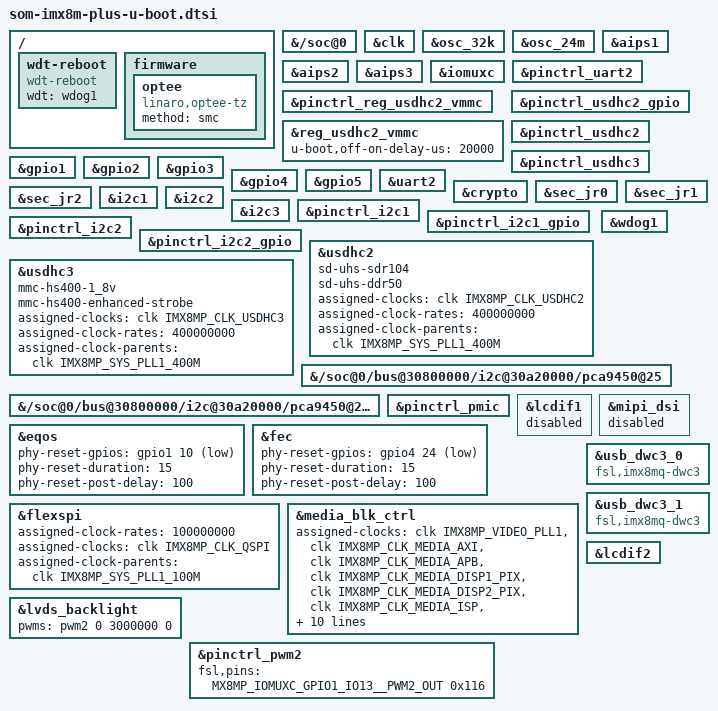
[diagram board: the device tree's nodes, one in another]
// SPDX-License-Identifier: GPL-2.0+
/*
 * Copyright 2019 NXP
 * Copyright 2021 CompuLab
 */

#include "imx8mp-sec-def.h"
#include "imx8mp-u-boot.dtsi"
/delete-node/ &binman;
#include "compulab-imx8mp-binman.dtsi"

/ {
	wdt-reboot {
		compatible = "wdt-reboot";
		wdt = <&wdog1>;
		bootph-pre-ram;
	};

	firmware {
		optee {
			compatible = "linaro,optee-tz";
			method = "smc";
		};
	};
};

&{/soc@0} {
	bootph-all;
	bootph-pre-ram;
};

&clk {
	bootph-pre-ram;
	bootph-all;
	/delete-property/ assigned-clocks;
	/delete-property/ assigned-clock-parents;
	/delete-property/ assigned-clock-rates;

};

&osc_32k {
	bootph-pre-ram;
	bootph-all;
};

&osc_24m {
	bootph-pre-ram;
	bootph-all;
};

&aips1 {
	bootph-pre-ram;
	bootph-all;
};

&aips2 {
	bootph-pre-ram;
};

&aips3 {
	bootph-pre-ram;
};

&iomuxc {
	bootph-pre-ram;
};

&pinctrl_reg_usdhc2_vmmc {
	bootph-pre-ram;
};

&reg_usdhc2_vmmc {
	bootph-pre-ram;
	u-boot,off-on-delay-us = <20000>;
};

&pinctrl_uart2 {
	bootph-pre-ram;
};

&pinctrl_usdhc2_gpio {
	bootph-pre-ram;
};

&pinctrl_usdhc2 {
	bootph-pre-ram;
};

&pinctrl_usdhc3 {
	bootph-pre-ram;
};

&gpio1 {
	bootph-pre-ram;
};

&gpio2 {
	bootph-pre-ram;
};

&gpio3 {
	bootph-pre-ram;
};

&gpio4 {
	bootph-pre-ram;
};

&gpio5 {
	bootph-pre-ram;
};

&uart2 {
	bootph-pre-ram;
};

&crypto {
	bootph-pre-ram;
};

&sec_jr0 {
	bootph-pre-ram;
};

&sec_jr1 {
	bootph-pre-ram;
};

&sec_jr2 {
	bootph-pre-ram;
};

&i2c1 {
	bootph-pre-ram;
};

&i2c2 {
	bootph-pre-ram;
};

&i2c3 {
	bootph-pre-ram;
};

&pinctrl_i2c1 {
	bootph-pre-ram;
};

&pinctrl_i2c1_gpio {
	bootph-pre-ram;
};

&pinctrl_i2c2 {
	bootph-pre-ram;
};

&pinctrl_i2c2_gpio {
	bootph-pre-ram;
};

&usdhc2 {
	bootph-pre-ram;
	sd-uhs-sdr104;
	sd-uhs-ddr50;
	assigned-clocks = <&clk IMX8MP_CLK_USDHC2>;
	assigned-clock-rates = <400000000>;
	assigned-clock-parents = <&clk IMX8MP_SYS_PLL1_400M>;
};

&usdhc3 {
	bootph-pre-ram;
	mmc-hs400-1_8v;
	mmc-hs400-enhanced-strobe;
	assigned-clocks = <&clk IMX8MP_CLK_USDHC3>;
	assigned-clock-rates = <400000000>;
	assigned-clock-parents = <&clk IMX8MP_SYS_PLL1_400M>;
};

&wdog1 {
	bootph-pre-ram;
};

&{/soc@0/bus@30800000/i2c@30a20000/pca9450@25} {
	bootph-pre-ram;
};

&{/soc@0/bus@30800000/i2c@30a20000/pca9450@25/regulators} {
	bootph-pre-ram;
};

&pinctrl_pmic {
	bootph-pre-ram;
};

&eqos {

	phy-reset-gpios = <&gpio1 10 GPIO_ACTIVE_LOW>;
	phy-reset-duration = <15>;
	phy-reset-post-delay = <100>;
};

&fec {
	phy-reset-gpios = <&gpio4 24 GPIO_ACTIVE_LOW>;
	phy-reset-duration = <15>;
	phy-reset-post-delay = <100>;
};

&flexspi {
	assigned-clock-rates = <100000000>;
	assigned-clocks = <&clk IMX8MP_CLK_QSPI>;
	assigned-clock-parents = <&clk IMX8MP_SYS_PLL1_100M>;
};

&lcdif1 {
	/delete-property/ assigned-clocks;
	/delete-property/ assigned-clock-parents;
	/delete-property/ assigned-clock-rates;
};

&mipi_dsi {
	/delete-property/ assigned-clocks;
	/delete-property/ assigned-clock-parents;
	/delete-property/ assigned-clock-rates;
};

/* Startec LVDS boot display clock configuration. */
&media_blk_ctrl {
	/* Set the PLL before calculating its downstream dividers. */
	assigned-clocks = <&clk IMX8MP_VIDEO_PLL1>,
			  <&clk IMX8MP_CLK_MEDIA_AXI>,
			  <&clk IMX8MP_CLK_MEDIA_APB>,
			  <&clk IMX8MP_CLK_MEDIA_DISP1_PIX>,
			  <&clk IMX8MP_CLK_MEDIA_DISP2_PIX>,
			  <&clk IMX8MP_CLK_MEDIA_ISP>,
			  <&clk IMX8MP_CLK_MEDIA_LDB>;
	assigned-clock-parents = <0>,
				 <&clk IMX8MP_SYS_PLL2_1000M>,
				 <&clk IMX8MP_SYS_PLL1_800M>,
				 <&clk IMX8MP_VIDEO_PLL1_OUT>,
				 <&clk IMX8MP_VIDEO_PLL1_OUT>,
				 <&clk IMX8MP_SYS_PLL2_500M>,
				 <&clk IMX8MP_VIDEO_PLL1_OUT>;
	assigned-clock-rates = <594000000>, <500000000>,
			       <200000000>, <0>, <42428571>,
			       <500000000>, <297000000>;
};

&usb_dwc3_0 {
	compatible = "fsl,imx8mq-dwc3", "snps,dwc3";
};

&usb_dwc3_1 {
	compatible = "fsl,imx8mq-dwc3", "snps,dwc3";
};


// Startec 1024x600 LVDS is the sole U-Boot display.
#include "compulab-imx8m-plus-lcdif2.dtsi"

/ {
	/delete-node/ dsi-host;
	/delete-node/ ili9881c_panel;
	/delete-node/ backlight;
};

&lcdif1 {
	status = "disabled";
};

&mipi_dsi {
	status = "disabled";
	/delete-node/ port@1;
};

&lcdif2 {
	status = "okay";
};

&lvds_backlight {
	pwms = <&pwm2 0 3000000 0>;
};

/* CL-SOM carrier routes the backlight PWM to GPIO1_IO13. */
&pinctrl_pwm2 {
	fsl,pins = <MX8MP_IOMUXC_GPIO1_IO13__PWM2_OUT 0x116>;
};
